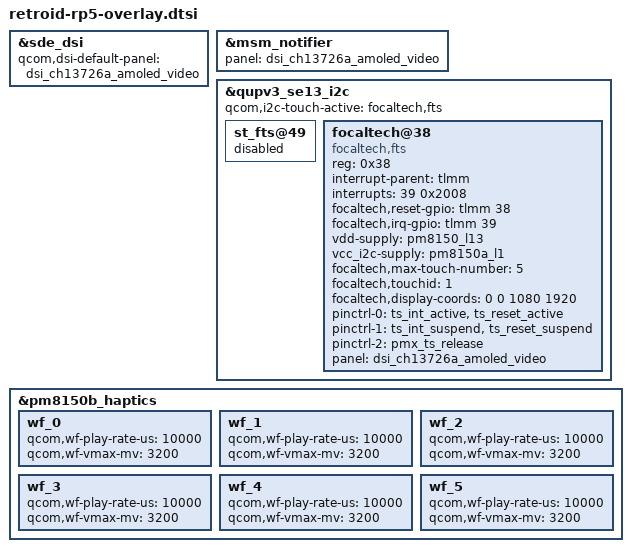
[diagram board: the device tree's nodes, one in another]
#include "moorechip-overlay.dtsi"

&sde_dsi {
	qcom,dsi-default-panel = <&dsi_ch13726a_amoled_video>;
};

&msm_notifier {
	panel = <&dsi_ch13726a_amoled_video>;
};

&qupv3_se13_i2c {
	qcom,i2c-touch-active = "focaltech,fts";

	st_fts@49 {
		status = "disabled";
	};

	focaltech@38 {
		compatible = "focaltech,fts";
		reg = <0x38>;
		interrupt-parent = <&tlmm>;
		interrupts = <39 0x2008>;
		focaltech,reset-gpio = <&tlmm 38 0x00>;
		focaltech,irq-gpio = <&tlmm 39 0x2008>;
		vdd-supply = <&pm8150_l13>;
		vcc_i2c-supply = <&pm8150a_l1>;
		focaltech,max-touch-number = <5>;
		focaltech,touchid = <1>;
		focaltech,display-coords = <0 0 1080 1920>;
		pinctrl-names = "pmx_ts_active", "pmx_ts_suspend", "pmx_ts_release";
		pinctrl-0 = <&ts_int_active &ts_reset_active>;
		pinctrl-1 = <&ts_int_suspend &ts_reset_suspend>;
		pinctrl-2 = <&pmx_ts_release>;
		panel = <&dsi_ch13726a_amoled_video>;
	};
};

&pm8150b_haptics {
	wf_0 {
		/* CLICK */
		qcom,wf-play-rate-us = <10000>;
		qcom,wf-vmax-mv = <3200>;
	};

	wf_1 {
		/* DOUBLE CLICK */
		qcom,wf-play-rate-us = <10000>;
		qcom,wf-vmax-mv = <3200>;
	};

	wf_2 {
		/* TICK */
		qcom,wf-play-rate-us = <10000>;
		qcom,wf-vmax-mv = <3200>;
	};

	wf_3 {
		/* THUD */
		qcom,wf-play-rate-us = <10000>;
		qcom,wf-vmax-mv = <3200>;
	};

	wf_4 {
		/* POP */
		qcom,wf-play-rate-us = <10000>;
		qcom,wf-vmax-mv = <3200>;
	};

	wf_5 {
		/* HEAVY CLICK */
		qcom,wf-play-rate-us = <10000>;
		qcom,wf-vmax-mv = <3200>;
	};
};
